# STM32F446 register map
File version: 1.1
CPU: CM4 r1p0, little endian, no MPU, no FPU, 4 interrupt priority bits
Registers are 32-bit, read-write, reset 0x0 unless marked. A register's access mark holds for its fields unless they carry their own. Offsets are from the block's base; lines under a group give offsets from that group; [hi:lo] are bit positions; {n}, {i} and the like mark numbered series; 'fields as' and 'values as' point back to an identical list; <NAME> marks a mode.

## Memory map
0x50000000 OTG_FS_GLOBAL size 0x400 — USB on the go full speed
0x50000400 OTG_FS_HOST size 0x400 — USB on the go full speed
0x50000800 OTG_FS_DEVICE size 0x400 — USB on the go full speed
0x50000E00 OTG_FS_PWRCLK size 0x400 — USB on the go full speed

## OTG_FS_HOST — USB on the go full speed
Base 0x50000400
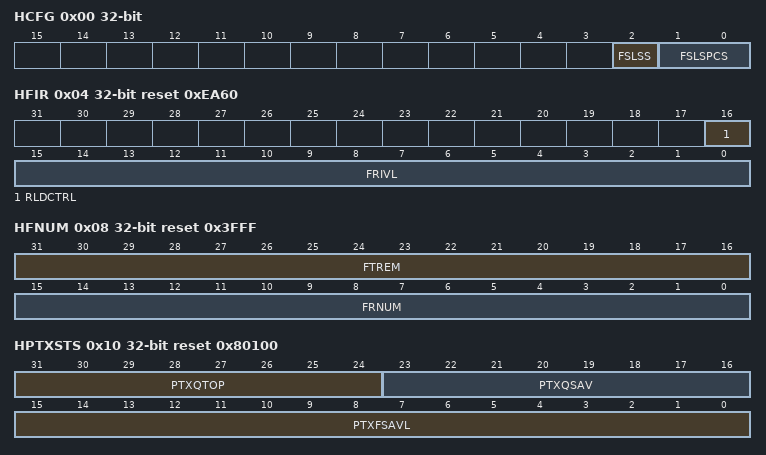
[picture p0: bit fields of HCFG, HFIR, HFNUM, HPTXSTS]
0x00 HCFG access per field — OTG host configuration register
  [2] FSLSS ro — FS- and LS-only support
  [1:0] FSLSPCS rw — FS/LS PHY clock select
0x04 HFIR reset 0xEA60 — OTG Host frame interval register
  [16] RLDCTRL — Reload control
  [15:0] FRIVL — Frame interval
0x08 HFNUM ro reset 0x3FFF — OTG host frame number/frame time remaining register
  [31:16] FTREM — Frame time remaining
  [15:0] FRNUM — Frame number
0x10 HPTXSTS ro reset 0x80100 — OTG host periodic transmit FIFO/queue status register
  [31:24] PTXQTOP — Top of the periodic transmit request queue
  [23:16] PTXQSAV — Periodic transmit request queue space available
  [15:0] PTXFSAVL — Periodic transmit data FIFO space available
0x14 HAINT ro — OTG host all channels interrupt register
  [15:0] HAINT — Channel interrupts
0x18 HAINTMSK — OTG host all channels interrupt mask register
  [15:0] HAINTM — Channel interrupt mask
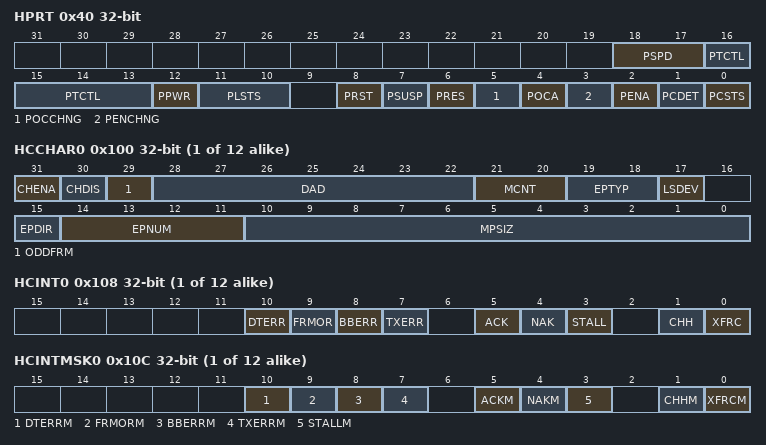
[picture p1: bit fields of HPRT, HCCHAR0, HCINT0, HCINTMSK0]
0x40 HPRT access per field — OTG host port control and status register
  [18:17] PSPD ro — Port speed
  [16:13] PTCTL rw — Port test control
  [12] PPWR rw — Port power
  [11:10] PLSTS ro — Port line status
  [8] PRST rw — Port reset
  [7] PSUSP rw — Port suspend
  [6] PRES rw — Port resume
  [5] POCCHNG rw — Port overcurrent change
  [4] POCA ro — Port overcurrent active
  [3] PENCHNG rw — Port enable/disable change
  [2] PENA rw — Port enable
  [1] PCDET rw — Port connect detected
  [0] PCSTS ro — Port connect status
{0x100+0x20*i} HCCHAR{i} (i=0..11) — OTG host channel x characteristics register
  [31] CHENA — Channel enable
  [30] CHDIS — Channel disable
  [29] ODDFRM — Odd frame
  [28:22] DAD — Device address
  [21:20] MCNT — Multicount
  [19:18] EPTYP — Endpoint type
  [17] LSDEV — Low-speed device
  [15] EPDIR — Endpoint direction
  [14:11] EPNUM — Endpoint number
  [10:0] MPSIZ — Maximum packet size
{0x108+0x20*i} HCINT{i} (i=0..11) — OTG host channel x interrupt register
  [10] DTERR — Data toggle error
  [9] FRMOR — Frame overrun
  [8] BBERR — Babble error
  [7] TXERR — Transaction error
  [5] ACK — ACK response received/transmitted interrupt
  [4] NAK — NAK response received interrupt
  [3] STALL — STALL response received interrupt
  [1] CHH — Channel halted
  [0] XFRC — Transfer completed
{0x10C+0x20*i} HCINTMSK{i} (i=0..11) — OTG host channel x interrupt mask register
  [10] DTERRM — Data toggle error mask
  [9] FRMORM — Frame overrun mask
  [8] BBERRM — Babble error mask
  [7] TXERRM — Transaction error mask
  [5] ACKM — ACK response received/transmitted interrupt mask
  [4] NAKM — NAK response received interrupt mask
  [3] STALLM — STALL response received interrupt mask
  [1] CHHM — Channel halted mask
  [0] XFRCM — Transfer completed mask
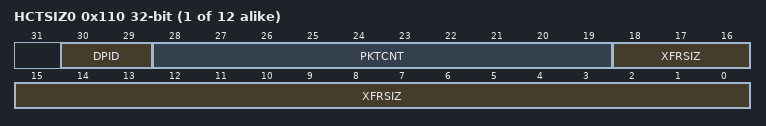
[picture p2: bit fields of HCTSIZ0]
{0x110+0x20*i} HCTSIZ{i} (i=0..11) — OTG host channel x transfer size register
  [30:29] DPID — Data PID
  [28:19] PKTCNT — Packet count
  [18:0] XFRSIZ — Transfer size

## OTG_FS_PWRCLK — USB on the go full speed
Base 0x50000E00
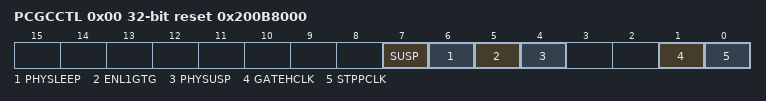
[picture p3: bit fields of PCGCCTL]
0x00 PCGCCTL access per field reset 0x200B8000 — OTG power and clock gating control register
  [7] SUSP ro — Deep Sleep
  [6] PHYSLEEP ro — PHY in Sleep
  [5] ENL1GTG rw — Enable sleep clock gating
  [4] PHYSUSP ro — PHY suspended
  [1] GATEHCLK rw
  [0] STPPCLK rw — Stop PHY clock
